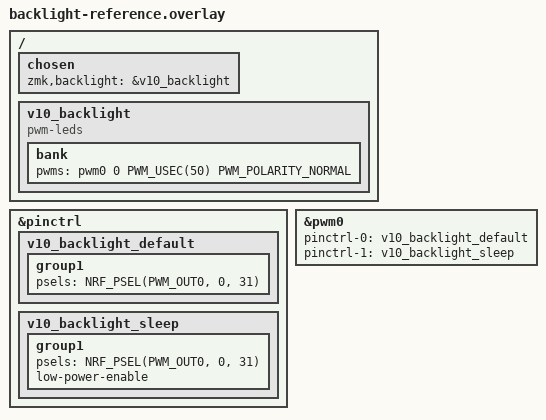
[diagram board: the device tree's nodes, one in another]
/* Reference only; merge with existing pinctrl/nodes rather than duplicating.
 * V10 netlist: BL_EN = module pin 20, P0.31. Verify the actual clone.
 * PWM drives the LED-bank MOSFET, NOT the switching regulator's enable.
 * 50 us = 20 kHz. Confirm PWM timing, low-duty linearity and driver transients.
 */
#include <zephyr/dt-bindings/pwm/pwm.h>
#include <zephyr/dt-bindings/pinctrl/nrf-pinctrl.h>

&pinctrl {
    v10_backlight_default: v10_backlight_default {
        group1 { psels = <NRF_PSEL(PWM_OUT0, 0, 31)>; };
    };
    v10_backlight_sleep: v10_backlight_sleep {
        group1 {
            psels = <NRF_PSEL(PWM_OUT0, 0, 31)>;
            low-power-enable;
        };
    };
};
&pwm0 {
    status = "okay";
    pinctrl-0 = <&v10_backlight_default>;
    pinctrl-1 = <&v10_backlight_sleep>;
    pinctrl-names = "default", "sleep";
};
/ {
    chosen { zmk,backlight = &v10_backlight; };
    v10_backlight: v10_backlight {
        compatible = "pwm-leds";
        bank {
            pwms = <&pwm0 0 PWM_USEC(50) PWM_POLARITY_NORMAL>;
        };
    };
};
